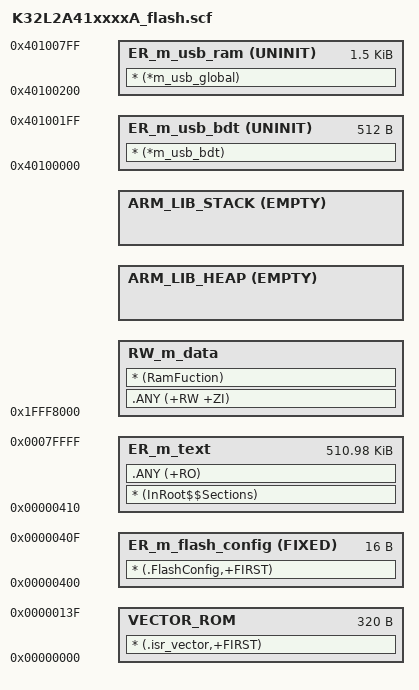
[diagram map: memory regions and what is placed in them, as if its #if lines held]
#!armclang --target=arm-arm-none-eabi -mcpu=cortex-m0plus -E -x c
/*
** ###################################################################
**     Processors:          K32L2A41VLH1A
**                          K32L2A41VLL1A
**
**     Compiler:            Keil ARM C/C++ Compiler
**     Reference manual:    K32L2AxRM, Rev. 1, 12/2019
**     Version:             rev. 1.0, 2019-10-30
**     Build:               b200914
**
**     Abstract:
**         Linker file for the Keil ARM C/C++ Compiler
**
**     Copyright 2016 Freescale Semiconductor, Inc.
**     Copyright 2016-2020 NXP
**     All rights reserved.
**
**     SPDX-License-Identifier: BSD-3-Clause
**
**     http:                 www.nxp.com
**     mail:                 support@nxp.com
**
** ###################################################################
*/

#define m_interrupts_start             0x00000000
#define m_interrupts_size              0x00000140

#define m_flash_config_start           0x00000400
#define m_flash_config_size            0x00000010

#define m_text_start                   0x00000410
#define m_text_size                    0x0007FBF0

#define m_data_start                   0x1FFF8000
#define m_data_size                    0x00020000

#define m_usb_sram_start               0x40100000
#define m_usb_sram_size                0x00000800

/* USB BDT size */
#define usb_bdt_size                   0x200
/* Sizes */
#if (defined(__stack_size__))
  #define Stack_Size                   __stack_size__
#else
  #define Stack_Size                   0x0400
#endif

#if (defined(__heap_size__))
  #define Heap_Size                    __heap_size__
#else
  #define Heap_Size                    0x0400
#endif

LR_m_text m_interrupts_start m_text_start+m_text_size-m_interrupts_start { ; load region size_region
  VECTOR_ROM m_interrupts_start m_interrupts_size { ; load address = execution address
    * (.isr_vector,+FIRST)
  }
  ER_m_flash_config m_flash_config_start FIXED m_flash_config_size { ; load address = execution address
    * (.FlashConfig,+FIRST)
  }
  ER_m_text m_text_start m_text_size { ; load address = execution address
    * (InRoot$$Sections)
    .ANY (+RO)
  }

  RW_m_data m_data_start m_data_size-Stack_Size-Heap_Size { ; RW data
    .ANY (+RW +ZI)
    * (RamFuction)
  }
  ARM_LIB_HEAP +0 EMPTY Heap_Size {    ; Heap region growing up
  }
  ARM_LIB_STACK m_data_start+m_data_size EMPTY -Stack_Size { ; Stack region growing down
  }
}

LR_m_usb_bdt m_usb_sram_start usb_bdt_size {
  ER_m_usb_bdt m_usb_sram_start UNINIT usb_bdt_size {
    * (*m_usb_bdt)
  }
}

LR_m_usb_ram (m_usb_sram_start + usb_bdt_size) (m_usb_sram_size - usb_bdt_size) {
  ER_m_usb_ram (m_usb_sram_start + usb_bdt_size) UNINIT (m_usb_sram_size - usb_bdt_size) {
    * (*m_usb_global)
  }
}

